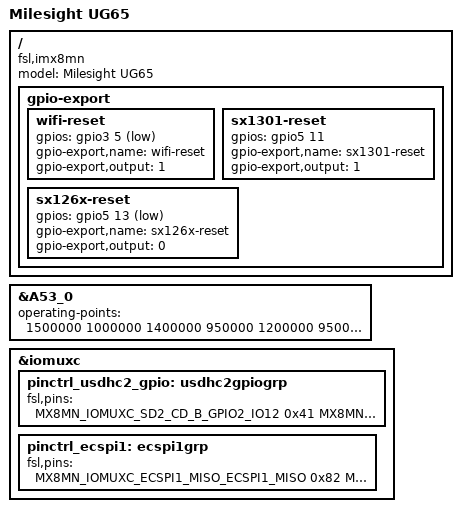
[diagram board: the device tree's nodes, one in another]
/dts-v1/;

#include "milesight-ug6x.dtsi"

/ {
	model = "Milesight UG65";
	compatible = "fsl,imx8mn";

	gpio-export {
		wifi-reset {
			gpios = <&gpio3 5 GPIO_ACTIVE_LOW>;
			gpio-export,name = "wifi-reset";
			gpio-export,output = <1>;
		};

		sx1301-reset {
			gpios = <&gpio5 11 (GPIO_ACTIVE_HIGH | GPIO_OPEN_DRAIN)>;
			gpio-export,name = "sx1301-reset";
			gpio-export,output = <1>;
		};

		sx126x-reset {
			gpios = <&gpio5 13 GPIO_ACTIVE_LOW>;
			gpio-export,name = "sx126x-reset";
			gpio-export,output = <0>;
		};
	};
};

&A53_0 {
	operating-points = <1500000 1000000 1400000 950000 1200000 950000 1000000 950000 800000 950000 600000 950000>;
};

&iomuxc {
	pinctrl_usdhc2_gpio: usdhc2gpiogrp {
		fsl,pins = <
			MX8MN_IOMUXC_SD2_CD_B_GPIO2_IO12        0x41
			MX8MN_IOMUXC_SD2_RESET_B_GPIO2_IO19     0x41 /* power_gpios_sd */
		>;
	};

	pinctrl_ecspi1: ecspi1grp {
		fsl,pins = <
			MX8MN_IOMUXC_ECSPI1_MISO_ECSPI1_MISO    0x82 /* SPI MISO */
			MX8MN_IOMUXC_ECSPI1_MOSI_ECSPI1_MOSI    0x82 /* SPI MOSI */
			MX8MN_IOMUXC_ECSPI1_SCLK_ECSPI1_SCLK    0x82 /* SPI SCLK */
			MX8MN_IOMUXC_ECSPI1_SS0_GPIO5_IO9	0x19
			MX8MN_IOMUXC_ECSPI2_MISO_GPIO5_IO12	0x19
			MX8MN_IOMUXC_GPIO1_IO03_GPIO1_IO3	0x19
			MX8MN_IOMUXC_SPDIF_RX_GPIO5_IO4		0x19
			MX8MN_IOMUXC_NAND_CLE_GPIO3_IO5		0x19 /* wifi-reset */
			MX8MN_IOMUXC_ECSPI2_SCLK_GPIO5_IO10     0x19 /* ? from decompiled ecspi1grp */
			MX8MN_IOMUXC_ECSPI2_MOSI_GPIO5_IO11     0x19 /* sx1301-reset */
			MX8MN_IOMUXC_ECSPI2_SS0_GPIO5_IO13      0x19 /* sx126x-reset */
			MX8MN_IOMUXC_NAND_READY_B_GPIO3_IO16    0x19 /* ? from decompiled ecspi1grp */
		>;
	};
};

